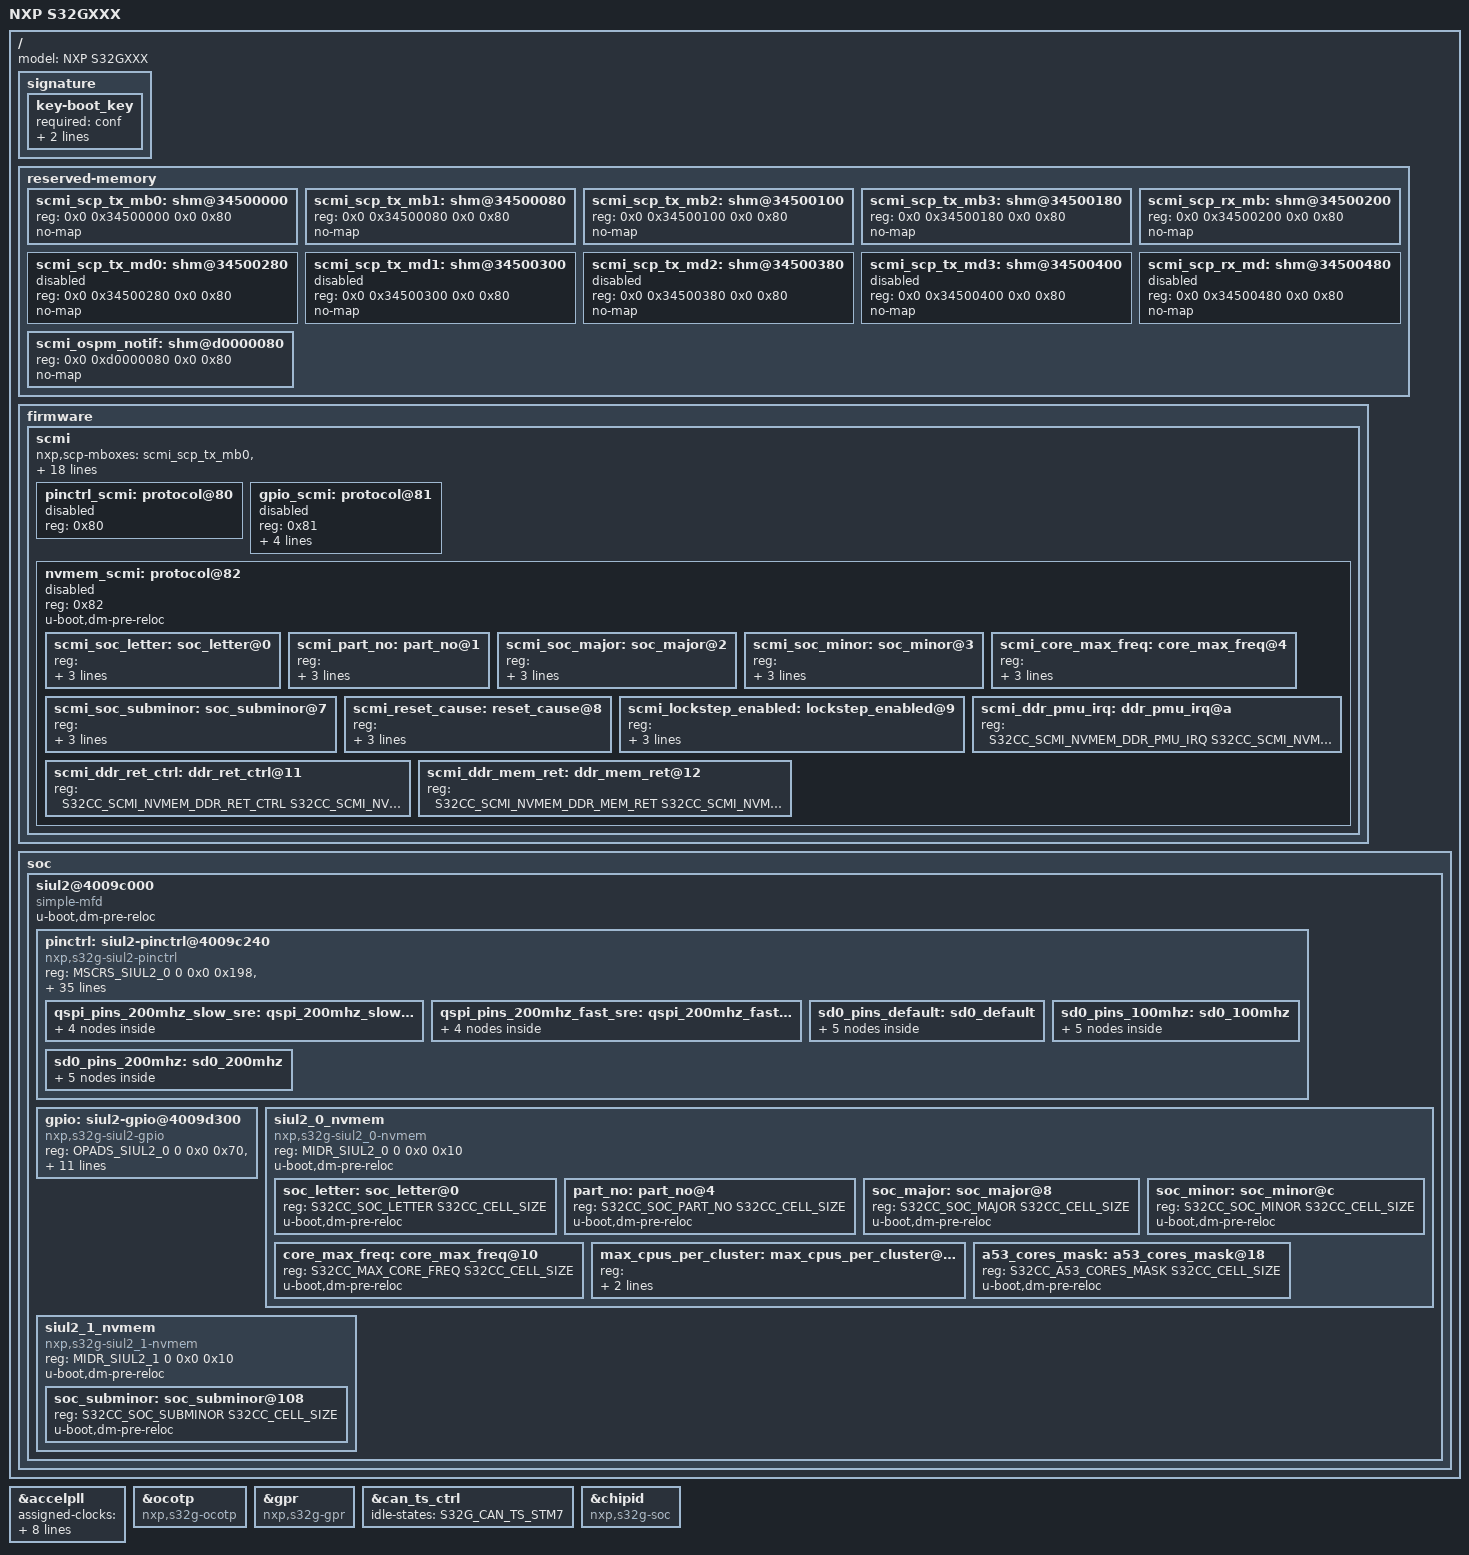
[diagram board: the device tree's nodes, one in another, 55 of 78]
// SPDX-License-Identifier: (GPL-2.0+ OR BSD-3-Clause)
/*
 * Copyright 2017-2026 NXP
 */
#include <dt-bindings/clock/s32g-clock.h>
#include <dt-bindings/clock/s32g-scmi-clock.h>
#include <dt-bindings/mux/nxp-s32g-can-ts.h>
#include <dt-bindings/nvmem/s32cc-scmi-nvmem.h>
#include <dt-bindings/nvmem/s32cc-siul2-nvmem.h>
#include <dt-bindings/nvmem/s32g-gpr-nvmem.h>
#include <dt-bindings/pinctrl/s32cc-pinfunc.h>
#include <dt-bindings/memory/s32-siul2.h>
#include <dt-bindings/reset/s32cc-scmi-reset.h>
#include <dt-bindings/mscm/s32cc-mscm.h>

#include "s32cc.dtsi"
/ {
	model = "NXP S32GXXX";

	signature {
		key-boot_key {
			required = "conf";
			algo = "sha1,rsa2048";
			key-name-hint = "boot_key";
		};
	};

	reserved-memory {
		#address-cells = <2>;
		#size-cells = <2>;
		ranges;

		/* SCP TX mailbox #0 */
		scmi_scp_tx_mb0: shm@34500000 {
			reg = <0x0 0x34500000 0x0 0x80>;
			no-map;
		};

		/* SCP TX mailbox #1 */
		scmi_scp_tx_mb1: shm@34500080 {
			reg = <0x0 0x34500080 0x0 0x80>;
			no-map;
		};

		/* SCP TX mailbox #2 */
		scmi_scp_tx_mb2: shm@34500100 {
			reg = <0x0 0x34500100 0x0 0x80>;
			no-map;
		};

		/* SCP TX mailbox #3 */
		scmi_scp_tx_mb3: shm@34500180 {
			reg = <0x0 0x34500180 0x0 0x80>;
			no-map;
		};

		/* SCP RX mailbox */
		scmi_scp_rx_mb: shm@34500200 {
			reg = <0x0 0x34500200 0x0 0x80>;
			no-map;
		};

		/* SCP TX metadata #0 */
		scmi_scp_tx_md0: shm@34500280 {
			reg = <0x0 0x34500280 0x0 0x80>;
			status = "disabled";
			no-map;
		};

		/* SCP TX metadata #1 */
		scmi_scp_tx_md1: shm@34500300 {
			reg = <0x0 0x34500300 0x0 0x80>;
			status = "disabled";
			no-map;
		};

		/* SCP TX metadata #2 */
		scmi_scp_tx_md2: shm@34500380 {
			reg = <0x0 0x34500380 0x0 0x80>;
			status = "disabled";
			no-map;
		};

		/* SCP TX metadata #3 */
		scmi_scp_tx_md3: shm@34500400 {
			reg = <0x0 0x34500400 0x0 0x80>;
			status = "disabled";
			no-map;
		};

		/* SCP RX metadata */
		scmi_scp_rx_md: shm@34500480 {
			reg = <0x0 0x34500480 0x0 0x80>;
			status = "disabled";
			no-map;
		};

		/* EL3 to EL1 notification */
		scmi_ospm_notif: shm@d0000080 {
			/* same size as the SCP RX mailbox */
			reg = <0x0 0xd0000080 0x0 0x80>;
			no-map;
		};
	};

	firmware {
		scmi {
			nxp,scp-mboxes = <&scmi_scp_tx_mb0>, <&scmi_scp_tx_md0>,
				<&scmi_scp_tx_mb1>, <&scmi_scp_tx_md1>,
				<&scmi_scp_tx_mb2>, <&scmi_scp_tx_md2>,
				<&scmi_scp_tx_mb3>, <&scmi_scp_tx_md3>,
				<&scmi_scp_rx_mb>, <&scmi_scp_rx_md>,
				<&scmi_ospm_notif>;
			nxp,scp-mbox-names = "scp_tx_mb0", "scp_tx_md0",
				"scp_tx_mb1", "scp_tx_md1",
				"scp_tx_mb2", "scp_tx_md2",
				"scp_tx_mb3", "scp_tx_md3",
				"scp_rx_mb", "scp_rx_md",
				"scmi_ospm_notif";
			/* <handle, cpn, irq> */
			nxp,scp-irqs = <&mscm0 M7_0_CPN MSCM_C2C_IRQ_1>,
				<&mscm0 A53_0_CPN MSCM_C2C_IRQ_1>,
				<&mscm0 M7_0_CPN MSCM_C2C_IRQ_1>,
				<&mscm0 M7_0_CPN MSCM_C2C_IRQ_2>,
				<&mscm0 A53_0_CPN MSCM_C2C_IRQ_2>;
			nxp,scp-irq-names = "scp_tx", "scp_rx", "scp_psci", "scp_ospm",
				"scp_ospm_rx";
			nxp,notif-irq = <GIC_SPI 300 IRQ_TYPE_EDGE_RISING>;

			pinctrl_scmi: protocol@80 {
				reg = <0x80>;
				#pinctrl-cells = <2>;
				status = "disabled";
			};

			gpio_scmi: protocol@81 {
				reg = <0x81>;
				#gpio-cells = <2>;
				gpio-controller;
				#interrupt-cells = <2>;
				#address-cells = <0>;
				interrupt-controller;

				/* GPIO ranges : 0-101 & 112-190 */
				gpio-ranges = <&pinctrl 0   0   102>,
					      <&pinctrl 112 112 79>;
				status = "disabled";
			};

			nvmem_scmi: protocol@82 {
				reg = <0x82>;
				#address-cells = <1>;
				#size-cells = <1>;
				status = "disabled";
				u-boot,dm-pre-reloc;
				bootph-all;

				scmi_soc_letter: soc_letter@0 {
					reg = <S32CC_SCMI_NVMEM_SOC_LETTER
						S32CC_SCMI_NVMEM_CELL_SIZE>;
					immutable;
					u-boot,dm-pre-reloc;
					bootph-all;
				};

				scmi_part_no: part_no@1 {
					reg = <S32CC_SCMI_NVMEM_SOC_PART_NO
						S32CC_SCMI_NVMEM_CELL_SIZE>;
					immutable;
					u-boot,dm-pre-reloc;
					bootph-all;
				};

				scmi_soc_major: soc_major@2 {
					reg = <S32CC_SCMI_NVMEM_SOC_MAJOR
						S32CC_SCMI_NVMEM_CELL_SIZE>;
					immutable;
					u-boot,dm-pre-reloc;
					bootph-all;
				};

				scmi_soc_minor: soc_minor@3 {
					reg = <S32CC_SCMI_NVMEM_SOC_MINOR
						S32CC_SCMI_NVMEM_CELL_SIZE>;
					immutable;
					u-boot,dm-pre-reloc;
					bootph-all;
				};

				scmi_core_max_freq: core_max_freq@4 {
					reg = <S32CC_SCMI_NVMEM_CORE_MAX_FREQ
						S32CC_SCMI_NVMEM_CELL_SIZE>;
					immutable;
					u-boot,dm-pre-reloc;
					bootph-all;
				};

				scmi_soc_subminor: soc_subminor@7 {
					reg = <S32CC_SCMI_NVMEM_SOC_SUBMINOR
						S32CC_SCMI_NVMEM_CELL_SIZE>;
					immutable;
					u-boot,dm-pre-reloc;
					bootph-all;
				};

				scmi_reset_cause: reset_cause@8 {
					reg = <S32CC_SCMI_NVMEM_RESET_CAUSE
						S32CC_SCMI_NVMEM_CELL_SIZE>;
					immutable;
					u-boot,dm-pre-reloc;
					bootph-all;
				};

				scmi_lockstep_enabled: lockstep_enabled@9 {
					reg = <S32CC_SCMI_NVMEM_LOCKSTEP_ENABLED
						S32CC_SCMI_NVMEM_CELL_SIZE>;
					immutable;
					u-boot,dm-pre-reloc;
					bootph-all;
				};

				scmi_ddr_pmu_irq: ddr_pmu_irq@a {
					reg = <S32CC_SCMI_NVMEM_DDR_PMU_IRQ
						S32CC_SCMI_NVMEM_CELL_SIZE>;
				};

				scmi_ddr_ret_ctrl: ddr_ret_ctrl@11 {
					reg = <S32CC_SCMI_NVMEM_DDR_RET_CTRL
						S32CC_SCMI_NVMEM_CELL_SIZE>;
				};

				scmi_ddr_mem_ret: ddr_mem_ret@12 {
					reg = <S32CC_SCMI_NVMEM_DDR_MEM_RET
						S32CC_SCMI_NVMEM_CELL_SIZE>;
				};
			};
		};
	};

	soc {
		siul2@4009c000 {
			compatible = "simple-mfd";
			u-boot,dm-pre-reloc;
			bootph-all;
			#address-cells = <2>;
			#size-cells = <2>;

				 /* MIDR */
			ranges = <MIDR_SIUL2_0 0x0 0x0 0x4009c000 0x0 0x10>,
				 <MIDR_SIUL2_1 0x0 0x0 0x44010000 0x0 0x10>,

				 /* MSCR 0-101 */
				 <MSCRS_SIUL2_0 0x0 0x0 0x4009c240 0x0 0x198>,
				 /* MSCR 112-122 */
				 <MSCRS_SIUL2_1_0 0x0 0x0 0x44010400 0x0 0x2c>,
				 /* MSCR 144-190 */
				 <MSCRS_SIUL2_1_1 0x0 0x0 0x44010480 0x0 0xbc>,

				 /* IMCR range 512 - 513 */
				 <IMCRS_SIUL2_0_0 0x0 0x0 0x4009ca40 0x0 0x8>,
				 /* IMCR range 515 - 573 */
				 <IMCRS_SIUL2_0_1 0x0 0x0 0x4009ca4c 0x0 0xec>,
				 /* IMCR range 580 - 595 */
				 <IMCRS_SIUL2_0_2 0x0 0x0 0x4009cb50 0x0 0x40>,
				 /* IMCR range 631 - 633 */
				 <IMCRS_SIUL2_1_0 0x0 0x0 0x44010c1c 0x0 0xc>,
				 /* IMCR range 640 - 641 */
				 <IMCRS_SIUL2_1_1 0x0 0x0 0x44010c40 0x0 0x8>,
				 /* IMCR range 655 - 663 */
				 <IMCRS_SIUL2_1_2 0x0 0x0 0x44010c7c 0x0 0x24>,
				 /* IMCR range 665 - 673 */
				 <IMCRS_SIUL2_1_3 0x0 0x0 0x44010ca4 0x0 0x24>,
				 /* IMCR range 717 - 724 */
				 <IMCRS_SIUL2_1_4 0x0 0x0 0x44010d74 0x0 0x20>,
				 /* IMCR range 736 - 737 */
				 <IMCRS_SIUL2_1_5 0x0 0x0 0x44010dc0 0x0 0x8>,
				 /* IMCR range 745 - 760 */
				 <IMCRS_SIUL2_1_6 0x0 0x0 0x44010de4 0x0 0x40>,
				 /* IMCR range 785 - 786 */
				 <IMCRS_SIUL2_1_7 0x0 0x0 0x44010e84 0x0 0x8>,
				 /* IMCR range 790 - 793 */
				 <IMCRS_SIUL2_1_8 0x0 0x0 0x44010e98 0x0 0x10>,
				 /* IMCR range 795 - 798 */
				 <IMCRS_SIUL2_1_9 0x0 0x0 0x44010eac 0x0 0x10>,
				 /* IMCR range 800 - 806 */
				 <IMCRS_SIUL2_1_10 0x0 0x0 0x44010ec0 0x0 0x1c>,
				 /* IMCR range 808 - 814 */
				 <IMCRS_SIUL2_1_11 0x0 0x0 0x44010ee0 0x0 0x1c>,
				 /* IMCR range 816 - 822 */
				 <IMCRS_SIUL2_1_12 0x0 0x0 0x44010f00 0x0 0x1c>,
				 /* IMCR range 824 - 826 */
				 <IMCRS_SIUL2_1_13 0x0 0x0 0x44010f20 0x0 0xc>,
				 /* IMCR range 828 - 828 */
				 <IMCRS_SIUL2_1_14 0x0 0x0 0x44010f30 0x0 0x4>,
				 /* IMCR range 830 - 830 */
				 <IMCRS_SIUL2_1_15 0x0 0x0 0x44010f38 0x0 0x4>,
				 /* IMCR range 834 - 852 */
				 <IMCRS_SIUL2_1_16 0x0 0x0 0x44010f48 0x0 0x4c>,
				 /* IMCR range 855 - 872 */
				 <IMCRS_SIUL2_1_17 0x0 0x0 0x44010f9c 0x0 0x48>,
				 /* IMCR range 875 - 892 */
				 <IMCRS_SIUL2_1_18 0x0 0x0 0x44010fec 0x0 0x48>,
				 /* IMCR range 895 - 905 */
				 <IMCRS_SIUL2_1_19 0x0 0x0 0x4401103c 0x0 0x2c>,
				 /* IMCR range 910 - 941 */
				 <IMCRS_SIUL2_1_EIRQS 0x0 0x0 0x44011078 0x0 0x80>,
				 /* IMCR range 942 - 945 */
				 <IMCRS_SIUL2_1_21 0x0 0x0 0x440110f8 0x0 0x10>,
				 /* IMCR range 979 - 982 */
				 <IMCRS_SIUL2_1_22 0x0 0x0 0x4401118c 0x0 0x10>,
				 /* IMCR range 985 - 987 */
				 <IMCRS_SIUL2_1_23 0x0 0x0 0x440111a4 0x0 0xc>,
				 /* IMCR range 990 - 992 */
				 <IMCRS_SIUL2_1_24 0x0 0x0 0x440111b8 0x0 0xc>,
				 /* IMCR range 995 - 997 */
				 <IMCRS_SIUL2_1_25 0x0 0x0 0x440111cc 0x0 0xc>,
				 /* IMCR range 1000 - 1002 */
				 <IMCRS_SIUL2_1_26 0x0 0x0 0x440111e0 0x0 0xc>,
				 /* IMCR range 1005 - 1007 */
				 <IMCRS_SIUL2_1_27 0x0 0x0 0x440111f4 0x0 0xc>,

				 /* Output pads (GPDO, one byte-wide register per pad) */
				 <OPADS_SIUL2_0 0x0 0x0 0x4009d300 0x0 0x70>,
				 <OPADS_SIUL2_1 0x0 0x0 0x44011300 0x0 0xc0>,

				 /* Input pads (GPDI, one byte-wide register per pad) */
				 <IPADS_SIUL2_0 0x0 0x0 0x4009d500 0x0 0x70>,
				 <IPADS_SIUL2_1 0x0 0x0 0x44011500 0x0 0xc0>,

				 /* EIRQs */
				 <EIRQS_SIUL2_1 0x0 0x0 0x44010010 0x0 0xb4>;

			pinctrl: siul2-pinctrl@4009c240 {
				compatible = "nxp,s32g-siul2-pinctrl",
					     "nxp,s32cc-siul2-pinctrl";
				#pinctrl-cells = <2>;

				reg = <MSCRS_SIUL2_0    0 0x0 0x198>,
				      <MSCRS_SIUL2_1_0  0 0x0 0x2c>,
				      <MSCRS_SIUL2_1_1  0 0x0 0xbc>,
				      <IMCRS_SIUL2_0_0  0 0x0 0x8>,
				      <IMCRS_SIUL2_0_1  0 0x0 0xec>,
				      <IMCRS_SIUL2_0_2  0 0x0 0x40>,
				      <IMCRS_SIUL2_1_0  0 0x0 0xc>,
				      <IMCRS_SIUL2_1_1  0 0x0 0x8>,
				      <IMCRS_SIUL2_1_2  0 0x0 0x24>,
				      <IMCRS_SIUL2_1_3  0 0x0 0x24>,
				      <IMCRS_SIUL2_1_4  0 0x0 0x20>,
				      <IMCRS_SIUL2_1_5  0 0x0 0x8>,
				      <IMCRS_SIUL2_1_6  0 0x0 0x40>,
				      <IMCRS_SIUL2_1_7  0 0x0 0x8>,
				      <IMCRS_SIUL2_1_8  0 0x0 0x10>,
				      <IMCRS_SIUL2_1_9  0 0x0 0x10>,
				      <IMCRS_SIUL2_1_10 0 0x0 0x1c>,
				      <IMCRS_SIUL2_1_11 0 0x0 0x1c>,
				      <IMCRS_SIUL2_1_12 0 0x0 0x1c>,
				      <IMCRS_SIUL2_1_13 0 0x0 0xc>,
				      <IMCRS_SIUL2_1_14 0 0x0 0x4>,
				      <IMCRS_SIUL2_1_15 0 0x0 0x4>,
				      <IMCRS_SIUL2_1_16 0 0x0 0x4c>,
				      <IMCRS_SIUL2_1_17 0 0x0 0x48>,
				      <IMCRS_SIUL2_1_18 0 0x0 0x48>,
				      <IMCRS_SIUL2_1_19 0 0x0 0x2c>,
				      <IMCRS_SIUL2_1_21 0 0x0 0x10>,
				      <IMCRS_SIUL2_1_22 0 0x0 0x10>,
				      <IMCRS_SIUL2_1_23 0 0x0 0xc>,
				      <IMCRS_SIUL2_1_24 0 0x0 0xc>,
				      <IMCRS_SIUL2_1_25 0 0x0 0xc>,
				      <IMCRS_SIUL2_1_26 0 0x0 0xc>,
				      <IMCRS_SIUL2_1_27 0 0x0 0xc>;

				/* MSCR range */
				nxp,pins = <0   101
					    112 122
					    144 190
				/* IMCR range */
					    512 513
					    515 573
					    580 595
					    631 633
					    640 641
					    655 663
					    665 673
					    717 724
					    736 737
					    745 760
					    785 786
					    790 793
					    795 798
					    800 806
					    808 814
					    816 822
					    824 826
					    828 828
					    830 830
					    834 852
					    855 872
					    875 892
					    895 905
					    942 945
					    979 982
					    985 987
					    990 992
					    995 997
					    1000 1002
					    1005 1007>;
			};

			gpio: siul2-gpio@4009d300 {
				compatible = "nxp,s32g-siul2-gpio", "nxp,s32cc-siul2-gpio";

				reg = <OPADS_SIUL2_0        0 0x0 0x70>,
				      <OPADS_SIUL2_1        0 0x0 0xc0>,
				      <IPADS_SIUL2_0        0 0x0 0x70>,
				      <IPADS_SIUL2_1        0 0x0 0xc0>,
				      <EIRQS_SIUL2_1        0 0x0 0xb4>,
				      <IMCRS_SIUL2_1_EIRQS  0 0x0 0x80>;
				reg-names = "opads0", "opads1", "ipads0",
					    "ipads1", "eirqs", "eirq-imcrs";

				#gpio-cells = <2>;
				gpio-controller;
					/* GPIO 0-101 */
				gpio-ranges = <&pinctrl 0   0   102>,
					/* GPIO 112-190 */
					      <&pinctrl 112 112 79>;
				gpio-reserved-ranges = <102 10>,
						       <123 21>;

				interrupt-controller;
				#interrupt-cells = <2>;
				interrupts = <GIC_SPI 210 IRQ_TYPE_LEVEL_HIGH>;
			};

			siul2_0_nvmem: siul2_0_nvmem {
				reg = <MIDR_SIUL2_0 0 0x0 0x10>;
				#address-cells = <1>;
				#size-cells = <1>;

				compatible = "nxp,s32g-siul2_0-nvmem";
				u-boot,dm-pre-reloc;
				bootph-all;

				soc_letter: soc_letter@0 {
					reg = <S32CC_SOC_LETTER S32CC_CELL_SIZE>;
					u-boot,dm-pre-reloc;
					bootph-all;
				};

				part_no: part_no@4 {
					reg = <S32CC_SOC_PART_NO S32CC_CELL_SIZE>;
					u-boot,dm-pre-reloc;
					bootph-all;
				};

				soc_major: soc_major@8 {
					reg = <S32CC_SOC_MAJOR S32CC_CELL_SIZE>;
					u-boot,dm-pre-reloc;
					bootph-all;
				};

				soc_minor: soc_minor@c {
					reg = <S32CC_SOC_MINOR S32CC_CELL_SIZE>;
					u-boot,dm-pre-reloc;
					bootph-all;
				};

				core_max_freq: core_max_freq@10 {
					reg = <S32CC_MAX_CORE_FREQ S32CC_CELL_SIZE>;
					u-boot,dm-pre-reloc;
					bootph-all;
				};

				max_cpus_per_cluster: max_cpus_per_cluster@14 {
					reg = <S32CC_MAX_A53_CORES_PER_CLUSTER
					    S32CC_CELL_SIZE>;
					u-boot,dm-pre-reloc;
					bootph-all;
				};

				a53_cores_mask: a53_cores_mask@18 {
					reg = <S32CC_A53_CORES_MASK S32CC_CELL_SIZE>;
					u-boot,dm-pre-reloc;
					bootph-all;
				};
			};

			siul2_1_nvmem: siul2_1_nvmem {
				reg = <MIDR_SIUL2_1 0 0x0 0x10>;
				#address-cells = <1>;
				#size-cells = <1>;

				compatible = "nxp,s32g-siul2_1-nvmem";
				u-boot,dm-pre-reloc;
				bootph-all;

				soc_subminor: soc_subminor@108 {
					reg = <S32CC_SOC_SUBMINOR S32CC_CELL_SIZE>;
					u-boot,dm-pre-reloc;
					bootph-all;
				};
			};
		};

	};
};

&accelpll {
	assigned-clocks =
		<&plat_clks S32CC_CLK_ACCEL_PLL_MUX>,
		<&plat_clks S32CC_CLK_ACCEL_PLL_VCO>,
		<&plat_clks S32G_CLK_ACCEL_PLL_PHI0>,
		<&plat_clks S32G_CLK_ACCEL_PLL_PHI1>;
	assigned-clock-parents =
		<&plat_clks S32CC_CLK_FXOSC>;
	assigned-clock-rates =
		<0>,
		<1800000000>,
		<600000000>,
		<600000000>;
};

&pinctrl {
	u-boot,dm-pre-reloc;
	bootph-all;

	qspi_pins_200mhz_slow_sre: qspi_200mhz_slow_sre {
		qspi_200mhz_slow_sre_grp0 {
			pinmux = <S32CC_PINMUX(85, FUNC1)>,
				 <S32CC_PINMUX(86, FUNC1)>,
				 <S32CC_PINMUX(87, FUNC1)>,
				 <S32CC_PINMUX(88, FUNC1)>,
				 <S32CC_PINMUX(89, FUNC1)>,
				 <S32CC_PINMUX(90, FUNC1)>,
				 <S32CC_PINMUX(91, FUNC1)>,
				 <S32CC_PINMUX(92, FUNC1)>,
				 <S32CC_PINMUX(93, FUNC1)>;
			output-enable;
			input-enable;
			slew-rate = <S32CC_GPIO_1V8_SLEW_208MHZ>;
			bias-pull-down;
		};

		qspi_200mhz_slow_sre_grp1 {
			pinmux = <S32CC_PINMUX(96, FUNC1)>,
				 <S32CC_PINMUX(97, FUNC1)>,
				 <S32CC_PINMUX(98, FUNC1)>,
				 <S32CC_PINMUX(99, FUNC1)>;
			output-enable;
			/*
			 * Split SRE configuration SRE[2:0]=110
			 * for CLK and SRE[2:0]=000 for Data
			 */
			slew-rate = <S32CC_GPIO_1V8_SLEW_100MHZ>;
		};

		qspi_200mhz_slow_sre_grp2 {
			pinmux = <S32CC_PINMUX(100, FUNC1)>,
				 <S32CC_PINMUX(101, FUNC1)>;
			output-enable;
			slew-rate = <S32CC_GPIO_1V8_SLEW_208MHZ>;
			bias-pull-up;
		};

		qspi_200mhz_slow_sre_grp3 {
			pinmux = <S32CC_PINMUX(540, FUNC2)>,
				 <S32CC_PINMUX(541, FUNC2)>,
				 <S32CC_PINMUX(542, FUNC2)>,
				 <S32CC_PINMUX(543, FUNC2)>,
				 <S32CC_PINMUX(544, FUNC2)>,
				 <S32CC_PINMUX(545, FUNC2)>,
				 <S32CC_PINMUX(546, FUNC2)>,
				 <S32CC_PINMUX(547, FUNC2)>,
				 <S32CC_PINMUX(548, FUNC2)>;
		};
	};

	qspi_pins_200mhz_fast_sre: qspi_200mhz_fast_sre {
		qspi_200mhz_fast_sre_grp0 {
			pinmux = <S32CC_PINMUX(85, FUNC1)>,
				 <S32CC_PINMUX(86, FUNC1)>,
				 <S32CC_PINMUX(87, FUNC1)>,
				 <S32CC_PINMUX(88, FUNC1)>,
				 <S32CC_PINMUX(89, FUNC1)>,
				 <S32CC_PINMUX(90, FUNC1)>,
				 <S32CC_PINMUX(91, FUNC1)>,
				 <S32CC_PINMUX(92, FUNC1)>,
				 <S32CC_PINMUX(93, FUNC1)>;
			output-enable;
			input-enable;
			slew-rate = <S32CC_GPIO_1V8_SLEW_208MHZ>;
			bias-pull-down;
		};

		qspi_200mhz_fast_sre_grp1 {
			pinmux = <S32CC_PINMUX(96, FUNC1)>,
				 <S32CC_PINMUX(97, FUNC1)>,
				 <S32CC_PINMUX(98, FUNC1)>,
				 <S32CC_PINMUX(99, FUNC1)>;
			output-enable;
			/*
			 * Single SRE configuration SRE[2:0]=000
			 * for both Data & CLK
			 */
			slew-rate = <S32CC_GPIO_1V8_SLEW_208MHZ>;
		};

		qspi_200mhz_fast_sre_grp2 {
			pinmux = <S32CC_PINMUX(100, FUNC1)>,
				 <S32CC_PINMUX(101, FUNC1)>;
			output-enable;
			slew-rate = <S32CC_GPIO_1V8_SLEW_208MHZ>;
			bias-pull-up;
		};

		qspi_200mhz_fast_sre_grp3 {
			pinmux = <S32CC_PINMUX(540, FUNC2)>,
				 <S32CC_PINMUX(541, FUNC2)>,
				 <S32CC_PINMUX(542, FUNC2)>,
				 <S32CC_PINMUX(543, FUNC2)>,
				 <S32CC_PINMUX(544, FUNC2)>,
				 <S32CC_PINMUX(545, FUNC2)>,
				 <S32CC_PINMUX(546, FUNC2)>,
				 <S32CC_PINMUX(547, FUNC2)>,
				 <S32CC_PINMUX(548, FUNC2)>;
		};
	};

	sd0_pins_default: sd0_default {
		sd0_default_grp0 {
			pinmux = <S32CC_PINMUX(46, FUNC1)>,
				 <S32CC_PINMUX(56, FUNC1)>;
			output-enable;
			slew-rate = <S32CC_FAST_SLEW_150MHZ>;
			bias-pull-down;
		};

		sd0_default_grp1 {
			pinmux = <S32CC_PINMUX(47, FUNC1)>,
				 <S32CC_PINMUX(48, FUNC1)>,
				 <S32CC_PINMUX(49, FUNC1)>,
				 <S32CC_PINMUX(50, FUNC1)>,
				 <S32CC_PINMUX(51, FUNC1)>,
				 <S32CC_PINMUX(52, FUNC1)>,
				 <S32CC_PINMUX(53, FUNC1)>,
				 <S32CC_PINMUX(54, FUNC1)>,
				 <S32CC_PINMUX(55, FUNC1)>;
			output-enable;
			input-enable;
			slew-rate = <S32CC_FAST_SLEW_150MHZ>;
			bias-pull-up;
		};

		sd0_default_grp2 {
			pinmux = <S32CC_PINMUX(57, FUNC1)>;
			output-enable;
			slew-rate = <S32CC_FAST_SLEW_150MHZ>;
		};

		sd0_default_grp3 {
			pinmux = <S32CC_PINMUX(58, FUNC0)>;
			input-enable;
			slew-rate = <S32CC_FAST_SLEW_150MHZ>;
		};

		sd0_default_grp4 {
			pinmux = <S32CC_PINMUX(515, FUNC2)>,
				 <S32CC_PINMUX(516, FUNC2)>,
				 <S32CC_PINMUX(517, FUNC2)>,
				 <S32CC_PINMUX(518, FUNC2)>,
				 <S32CC_PINMUX(519, FUNC2)>,
				 <S32CC_PINMUX(520, FUNC2)>,
				 <S32CC_PINMUX(521, FUNC2)>,
				 <S32CC_PINMUX(522, FUNC2)>,
				 <S32CC_PINMUX(523, FUNC2)>,
				 <S32CC_PINMUX(524, FUNC2)>;
		};
	};

	sd0_pins_100mhz: sd0_100mhz {
		sd0_100mhz_grp0 {
			pinmux = <S32CC_PINMUX(46, FUNC1)>,
				 <S32CC_PINMUX(56, FUNC1)>;
			output-enable;
			slew-rate = <S32CC_FAST_SLEW_150MHZ>;
			bias-pull-down;
		};

		sd0_100mhz_grp1 {
			pinmux = <S32CC_PINMUX(47, FUNC1)>,
				 <S32CC_PINMUX(48, FUNC1)>,
				 <S32CC_PINMUX(49, FUNC1)>,
				 <S32CC_PINMUX(50, FUNC1)>,
				 <S32CC_PINMUX(51, FUNC1)>,
				 <S32CC_PINMUX(52, FUNC1)>,
				 <S32CC_PINMUX(53, FUNC1)>,
				 <S32CC_PINMUX(54, FUNC1)>,
				 <S32CC_PINMUX(55, FUNC1)>;
			output-enable;
			input-enable;
			slew-rate = <S32CC_FAST_SLEW_150MHZ>;
			bias-pull-up;
		};

		sd0_100mhz_grp2 {
			pinmux = <S32CC_PINMUX(57, FUNC1)>;
			output-enable;
			slew-rate = <S32CC_FAST_SLEW_150MHZ>;
		};

		sd0_100mhz_grp3 {
			pinmux = <S32CC_PINMUX(58, FUNC0)>;
			input-enable;
			slew-rate = <S32CC_FAST_SLEW_150MHZ>;
		};

		sd0_100mhz_grp4 {
			pinmux = <S32CC_PINMUX(515, FUNC2)>,
				 <S32CC_PINMUX(516, FUNC2)>,
				 <S32CC_PINMUX(517, FUNC2)>,
				 <S32CC_PINMUX(518, FUNC2)>,
				 <S32CC_PINMUX(519, FUNC2)>,
				 <S32CC_PINMUX(520, FUNC2)>,
				 <S32CC_PINMUX(521, FUNC2)>,
				 <S32CC_PINMUX(522, FUNC2)>,
				 <S32CC_PINMUX(523, FUNC2)>,
				 <S32CC_PINMUX(524, FUNC2)>;
		};
	};

	sd0_pins_200mhz: sd0_200mhz {
		sd0_200mhz_grp0 {
			pinmux = <S32CC_PINMUX(46, FUNC1)>,
				 <S32CC_PINMUX(56, FUNC1)>;
			output-enable;
			slew-rate = <S32CC_FAST_SLEW_100MHZ>;
			bias-pull-down;
		};

		sd0_200mhz_grp1 {
			pinmux = <S32CC_PINMUX(47, FUNC1)>,
				 <S32CC_PINMUX(48, FUNC1)>,
				 <S32CC_PINMUX(49, FUNC1)>,
				 <S32CC_PINMUX(50, FUNC1)>,
				 <S32CC_PINMUX(51, FUNC1)>,
				 <S32CC_PINMUX(52, FUNC1)>,
				 <S32CC_PINMUX(53, FUNC1)>,
				 <S32CC_PINMUX(54, FUNC1)>,
				 <S32CC_PINMUX(55, FUNC1)>;
			output-enable;
			input-enable;
			slew-rate = <S32CC_FAST_SLEW_208MHZ>;
			bias-pull-up;
		};

		sd0_200mhz_grp2 {
			pinmux = <S32CC_PINMUX(57, FUNC1)>;
			output-enable;
			slew-rate = <S32CC_FAST_SLEW_208MHZ>;
		};

		sd0_200mhz_grp3 {
			pinmux = <S32CC_PINMUX(58, FUNC0)>;
			input-enable;
			slew-rate = <S32CC_FAST_SLEW_208MHZ>;
		};

		sd0_200mhz_grp4 {
			pinmux = <S32CC_PINMUX(515, FUNC2)>,
				 <S32CC_PINMUX(516, FUNC2)>,
				 <S32CC_PINMUX(517, FUNC2)>,
				 <S32CC_PINMUX(518, FUNC2)>,
				 <S32CC_PINMUX(519, FUNC2)>,
				 <S32CC_PINMUX(520, FUNC2)>,
				 <S32CC_PINMUX(521, FUNC2)>,
				 <S32CC_PINMUX(522, FUNC2)>,
				 <S32CC_PINMUX(523, FUNC2)>,
				 <S32CC_PINMUX(524, FUNC2)>;
		};
	};
};

&ocotp {
	compatible = "nxp,s32g-ocotp";
};

&gpr {
	compatible = "nxp,s32g-gpr";
};

&can_ts_ctrl {
	idle-states = <S32G_CAN_TS_STM7>;
	status = "okay";
};

&chipid {
	compatible = "nxp,s32g-soc";
};
